AUTOSAR XML (schema 4-2-2)
package /ComponentTypes
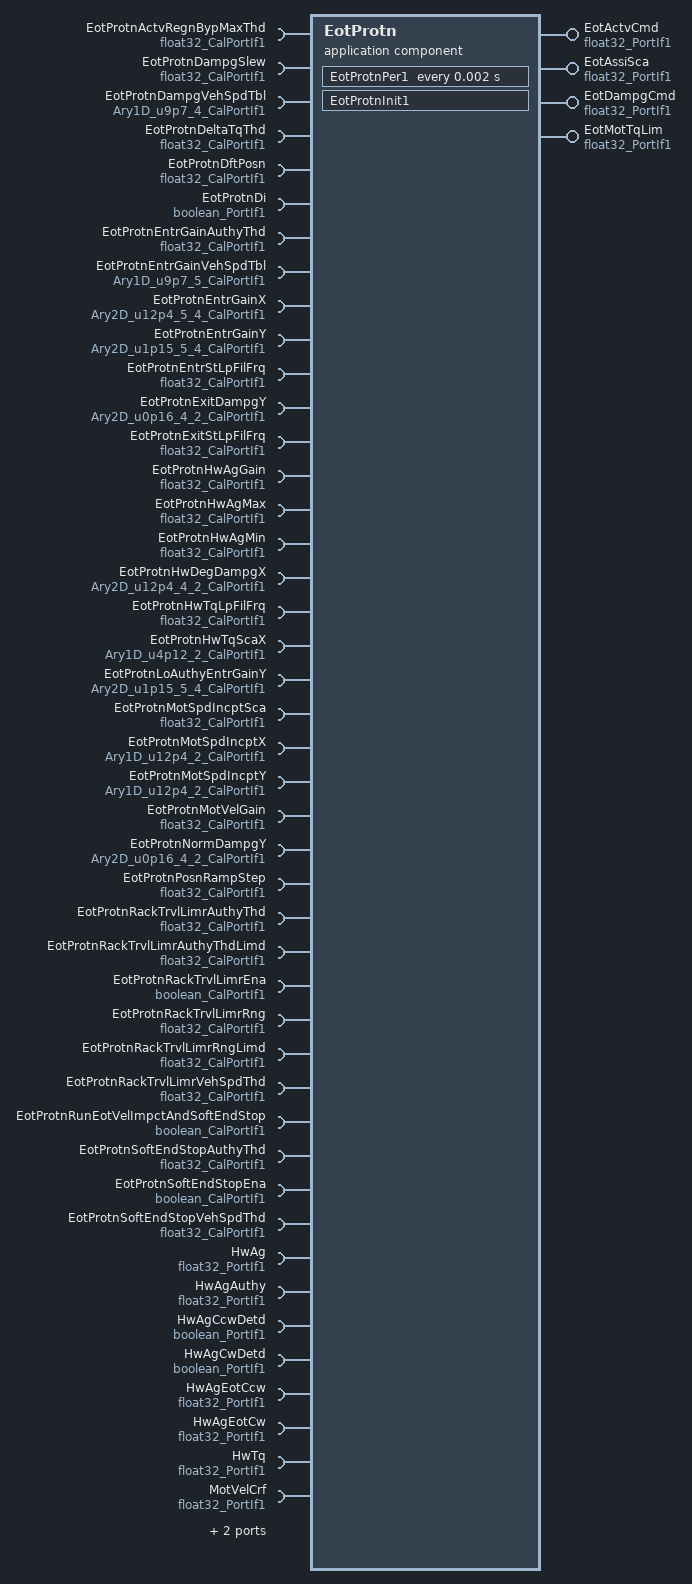
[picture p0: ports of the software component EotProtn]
  application sw component type EotProtn
    4 x provide port, all with nonqueued-sender-com-spec{data-element=Val, init-value=0}, provided-interface=float32_PortIf1:
      EotActvCmd
      EotAssiSca
      EotDampgCmd
      EotMotTqLim
    46 x require port:
      EotProtnActvRegnBypMaxThd: parameter-require-com-spec{init-value=0.5, parameter=Val}, required-interface=float32_CalPortIf1
      EotProtnDampgSlew: parameter-require-com-spec{init-value=400, parameter=Val}, required-interface=float32_CalPortIf1
      EotProtnDampgVehSpdTbl: parameter-require-com-spec{init-value=[0, 640, 1280, 2560], parameter=Ary1D}, required-interface=Ary1D_u9p7_4_CalPortIf1
      EotProtnDeltaTqThd: parameter-require-com-spec{init-value=0, parameter=Val}, required-interface=float32_CalPortIf1
      EotProtnDftPosn: parameter-require-com-spec{init-value=100, parameter=Val}, required-interface=float32_CalPortIf1
      EotProtnDi: nonqueued-receiver-com-spec{data-element=Logl, filter=data-filter-type=ALWAYS, init-value=0}, required-interface=boolean_PortIf1
      EotProtnEntrGainAuthyThd: parameter-require-com-spec{init-value=0.5, parameter=Val}, required-interface=float32_CalPortIf1
      EotProtnEntrGainVehSpdTbl: parameter-require-com-spec{init-value=[0, 640, 1280, 1920, 2560], parameter=Ary1D}, required-interface=Ary1D_u9p7_5_CalPortIf1
      EotProtnEntrGainX: parameter-require-com-spec{init-value=5 x [0, 480, 960, 1440], parameter=Ary2D}, required-interface=Ary2D_u12p4_5_4_CalPortIf1
      EotProtnEntrGainY: parameter-require-com-spec{init-value=5 x [0, 10813, 21627, 32768], parameter=Ary2D}, required-interface=Ary2D_u1p15_5_4_CalPortIf1
      EotProtnEntrStLpFilFrq: parameter-require-com-spec{init-value=30, parameter=Val}, required-interface=float32_CalPortIf1
      EotProtnExitDampgY: parameter-require-com-spec{init-value=[[0, 262], [0, 262], [0, 262], [0, 262]], parameter=Ary2D}, required-interface=Ary2D_u0p16_4_2_CalPortIf1
      EotProtnExitStLpFilFrq: parameter-require-com-spec{init-value=5, parameter=Val}, required-interface=float32_CalPortIf1
      EotProtnHwAgGain: parameter-require-com-spec{init-value=0.15, parameter=Val}, required-interface=float32_CalPortIf1
      EotProtnHwAgMax: parameter-require-com-spec{init-value=600, parameter=Val}, required-interface=float32_CalPortIf1
      EotProtnHwAgMin: parameter-require-com-spec{init-value=550, parameter=Val}, required-interface=float32_CalPortIf1
      EotProtnHwDegDampgX: parameter-require-com-spec{init-value=[[1920, 0], [1920, 0], [1920, 0], [1920, 0]], parameter=Ary2D}, required-interface=Ary2D_u12p4_4_2_CalPortIf1
      EotProtnHwTqLpFilFrq: parameter-require-com-spec{init-value=30, parameter=Val}, required-interface=float32_CalPortIf1
      EotProtnHwTqScaX: parameter-require-com-spec{init-value=[0, 4096], parameter=Ary1D}, required-interface=Ary1D_u4p12_2_CalPortIf1
      EotProtnLoAuthyEntrGainY: parameter-require-com-spec{init-value=5 x [0, 9830, 22938, 32768], parameter=Ary2D}, required-interface=Ary2D_u1p15_5_4_CalPortIf1
      EotProtnMotSpdIncptSca: parameter-require-com-spec{init-value=0.02, parameter=Val}, required-interface=float32_CalPortIf1
      EotProtnMotSpdIncptX: parameter-require-com-spec{init-value=[800, 400], parameter=Ary1D}, required-interface=Ary1D_u12p4_2_CalPortIf1
      EotProtnMotSpdIncptY: parameter-require-com-spec{init-value=[10400, 10400], parameter=Ary1D}, required-interface=Ary1D_u12p4_2_CalPortIf1
      EotProtnMotVelGain: parameter-require-com-spec{init-value=0.29, parameter=Val}, required-interface=float32_CalPortIf1
      EotProtnNormDampgY: parameter-require-com-spec{init-value=[[0, 262], [0, 262], [0, 262], [0, 262]], parameter=Ary2D}, required-interface=Ary2D_u0p16_4_2_CalPortIf1
      EotProtnPosnRampStep: parameter-require-com-spec{init-value=3, parameter=Val}, required-interface=float32_CalPortIf1
      EotProtnRackTrvlLimrAuthyThd: parameter-require-com-spec{init-value=1, parameter=Val}, required-interface=float32_CalPortIf1
      EotProtnRackTrvlLimrAuthyThdLimd: parameter-require-com-spec{init-value=1, parameter=Val}, required-interface=float32_CalPortIf1
      EotProtnRackTrvlLimrEna: parameter-require-com-spec{init-value=0, parameter=Logl}, required-interface=boolean_CalPortIf1
      EotProtnRackTrvlLimrRng: parameter-require-com-spec{init-value=90, parameter=Val}, required-interface=float32_CalPortIf1
      EotProtnRackTrvlLimrRngLimd: parameter-require-com-spec{init-value=20, parameter=Val}, required-interface=float32_CalPortIf1
      EotProtnRackTrvlLimrVehSpdThd: parameter-require-com-spec{init-value=20, parameter=Val}, required-interface=float32_CalPortIf1
      EotProtnRunEotVelImpctAndSoftEndStop: parameter-require-com-spec{init-value=0, parameter=Logl}, required-interface=boolean_CalPortIf1
      EotProtnSoftEndStopAuthyThd: parameter-require-com-spec{init-value=0.9, parameter=Val}, required-interface=float32_CalPortIf1
      EotProtnSoftEndStopEna: parameter-require-com-spec{init-value=0, parameter=Logl}, required-interface=boolean_CalPortIf1
      EotProtnSoftEndStopVehSpdThd: parameter-require-com-spec{init-value=30, parameter=Val}, required-interface=float32_CalPortIf1
      HwAg: nonqueued-receiver-com-spec{data-element=Val, filter=data-filter-type=ALWAYS, init-value=0}, required-interface=float32_PortIf1
      HwAgAuthy: nonqueued-receiver-com-spec{data-element=Val, filter=data-filter-type=ALWAYS, init-value=0}, required-interface=float32_PortIf1
      HwAgCcwDetd: nonqueued-receiver-com-spec{data-element=Logl, filter=data-filter-type=ALWAYS, init-value=0}, required-interface=boolean_PortIf1
      HwAgCwDetd: nonqueued-receiver-com-spec{data-element=Logl, filter=data-filter-type=ALWAYS, init-value=0}, required-interface=boolean_PortIf1
      HwAgEotCcw: nonqueued-receiver-com-spec{data-element=Val, filter=data-filter-type=ALWAYS, init-value=-360}, required-interface=float32_PortIf1
      HwAgEotCw: nonqueued-receiver-com-spec{data-element=Val, filter=data-filter-type=ALWAYS, init-value=360}, required-interface=float32_PortIf1
      HwTq: nonqueued-receiver-com-spec{data-element=Val, filter=data-filter-type=ALWAYS, init-value=0}, required-interface=float32_PortIf1
      MotVelCrf: nonqueued-receiver-com-spec{data-element=Val, filter=data-filter-type=ALWAYS, init-value=0}, required-interface=float32_PortIf1
      SysMotTqCmdSca: nonqueued-receiver-com-spec{data-element=Val, filter=data-filter-type=ALWAYS, init-value=1}, required-interface=float32_PortIf1
      VehSpd: nonqueued-receiver-com-spec{data-element=Val, filter=data-filter-type=ALWAYS, init-value=0}, required-interface=float32_PortIf1
    behavior EotProtn_InternalBehavior
      ar-typed-per-instance-memorys:
        17 x data, all with sw-calibration-access=READ-ONLY:
          dEotProtnDampg: type=float32
          dEotProtnDetd: type=boolean
          dEotProtnEntrGain: type=float32
          dEotProtnEotAssiSca: type=float32
          dEotProtnEotGain: type=float32
          dEotProtnExitGain: type=float32
          dEotProtnLimPosn: type=float32
          dEotProtnRackTrvlLimrDi: type=boolean
          EotAssiScaLpFil: type=FilLpRec1
          HwTqLpFil: type=FilLpRec1
          NewSoftEndStopSt: type=uint8
          PrevEotAssiSca: type=float32
          PrevEotDampg: type=float32
          PrevImpctPosn: type=float32
          PrevRackTrvlLimrEna: type=boolean
          PrevRackTrvlLimrInin: type=boolean
          PrevSoftEndStopSt: type=uint8
      init event EotProtn_InitEvent: start-on-event=EotProtnInit1
      timing event TMT_EotProtnPer1: start-on-event=EotProtnPer1, period=0.002
      port-api-options:
        enable-take-address=false, error-handling=NO-TRANSFORMER-ERROR-HANDLING, indirect-api=false, port=EotProtnRackTrvlLimrRng
        enable-take-address=false, error-handling=NO-TRANSFORMER-ERROR-HANDLING, indirect-api=false, port=SysMotTqCmdSca
      runnable EotProtnInit1
      runnable EotProtnPer1
        data-receive-point-by-arguments:
          11 x access:
            REC_EotProtnDi_Logl: accessed-variable=EotProtnDi.Logl
            REC_HwAg_Val: accessed-variable=HwAg.Val
            REC_HwAgAuthy_Val: accessed-variable=HwAgAuthy.Val
            REC_HwAgCcwDetd_Logl: accessed-variable=HwAgCcwDetd.Logl
            REC_HwAgCwDetd_Logl: accessed-variable=HwAgCwDetd.Logl
            REC_HwAgEotCcw_Val: accessed-variable=HwAgEotCcw.Val
            REC_HwAgEotCw_Val: accessed-variable=HwAgEotCw.Val
            REC_HwTq_Val: accessed-variable=HwTq.Val
            REC_MotVelCrf_Val: accessed-variable=MotVelCrf.Val
            REC_SysMotTqCmdSca_Val: accessed-variable=SysMotTqCmdSca.Val
            REC_VehSpd_Val: accessed-variable=VehSpd.Val
        data-send-points:
          4 x access:
            SEND_EotActvCmd_Val: accessed-variable=EotActvCmd.Val
            SEND_EotAssiSca_Val: accessed-variable=EotAssiSca.Val
            SEND_EotDampgCmd_Val: accessed-variable=EotDampgCmd.Val
            SEND_EotMotTqLim_Val: accessed-variable=EotMotTqLim.Val
  swc implementation EotProtn_Implementation: behavior=EotProtn_InternalBehavior
    code-descriptors:
      code Default: artifact-descriptors=autosar-engineering-object={short-label=Default, category=SWSRC}
